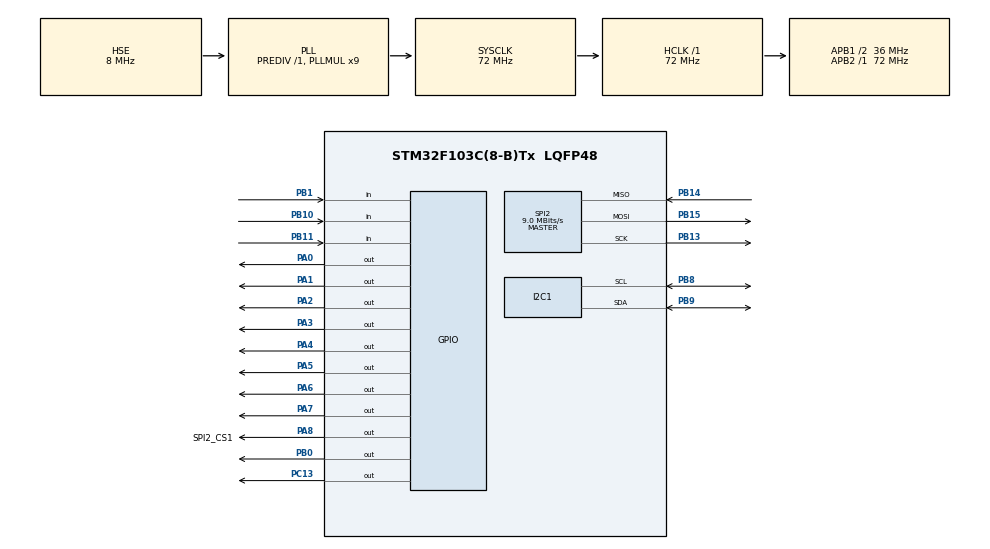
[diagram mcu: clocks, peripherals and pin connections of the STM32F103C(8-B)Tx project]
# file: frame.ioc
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Dma.I2C1_RX.0.Direction=DMA_PERIPH_TO_MEMORY
Dma.I2C1_RX.0.Instance=DMA1_Channel7
Dma.I2C1_RX.0.MemDataAlignment=DMA_MDATAALIGN_BYTE
Dma.I2C1_RX.0.MemInc=DMA_MINC_ENABLE
Dma.I2C1_RX.0.Mode=DMA_NORMAL
Dma.I2C1_RX.0.PeriphDataAlignment=DMA_PDATAALIGN_BYTE
Dma.I2C1_RX.0.PeriphInc=DMA_PINC_DISABLE
Dma.I2C1_RX.0.Priority=DMA_PRIORITY_LOW
Dma.I2C1_TX.1.Direction=DMA_MEMORY_TO_PERIPH
Dma.I2C1_TX.1.Instance=DMA1_Channel6
Dma.I2C1_TX.1.MemDataAlignment=DMA_MDATAALIGN_BYTE
Dma.I2C1_TX.1.MemInc=DMA_MINC_ENABLE
Dma.I2C1_TX.1.Mode=DMA_NORMAL
Dma.I2C1_TX.1.PeriphDataAlignment=DMA_PDATAALIGN_BYTE
Dma.I2C1_TX.1.PeriphInc=DMA_PINC_DISABLE
Dma.I2C1_TX.1.Priority=DMA_PRIORITY_LOW
Dma.Request0=I2C1_RX
Dma.Request1=I2C1_TX
Dma.Request2=SPI2_RX
Dma.Request3=SPI2_TX
Dma.SPI2_RX.2.Direction=DMA_PERIPH_TO_MEMORY
Dma.SPI2_RX.2.Instance=DMA1_Channel4
Dma.SPI2_RX.2.MemDataAlignment=DMA_MDATAALIGN_BYTE
Dma.SPI2_RX.2.MemInc=DMA_MINC_ENABLE
Dma.SPI2_RX.2.Mode=DMA_NORMAL
Dma.SPI2_RX.2.PeriphDataAlignment=DMA_PDATAALIGN_BYTE
Dma.SPI2_RX.2.PeriphInc=DMA_PINC_DISABLE
Dma.SPI2_RX.2.Priority=DMA_PRIORITY_LOW
Dma.SPI2_TX.3.Direction=DMA_MEMORY_TO_PERIPH
Dma.SPI2_TX.3.Instance=DMA1_Channel5
Dma.SPI2_TX.3.MemDataAlignment=DMA_MDATAALIGN_BYTE
Dma.SPI2_TX.3.MemInc=DMA_MINC_ENABLE
Dma.SPI2_TX.3.Mode=DMA_NORMAL
Dma.SPI2_TX.3.PeriphDataAlignment=DMA_PDATAALIGN_BYTE
Dma.SPI2_TX.3.PeriphInc=DMA_PINC_DISABLE
Dma.SPI2_TX.3.Priority=DMA_PRIORITY_LOW
FREERTOS.Mutexes01=IIC_LOCK,Dynamic,NULL
FREERTOS.Mutexes02=SPI_LOCK,Dynamic,NULL
FREERTOS.Queues01=KEY_EVT_Q,8,key_event_msg_t,0,Static,KEY_EVT_QBuffer,KEY_EVT_QControlBlock
FREERTOS.Tasks01=defaultTask,8,128,StartDefaultTask,As weak,NULL,Dynamic,NULL,NULL;KEY_T,48,128,Task_Key_Scan,As weak,NULL,Static,KEY_TBuffer,KEY_TControlBlock;KEY_CMD_T,40,128,Task_Key_Cmd,As weak,NULL,Static,KEY_CMD_TBuffer,KEY_CMD_TControlBlock;OLED_T,16,256,Task_OLED,As weak,NULL,Static,OLED_TBuffer,OLED_TControlBlock
FREERTOS.configMINIMAL_STACK_SIZE=64
I2C1.I2C_Mode=I2C_Fast
Mcu.Family=STM32F1
Mcu.Name=STM32F103C(8-B)Tx
Mcu.Package=LQFP48
NVIC.DMA1_Channel4_IRQn=true\:5\:0\:false\:false\:true\:true\:false\:true\:true
NVIC.DMA1_Channel5_IRQn=true\:5\:0\:false\:false\:true\:true\:false\:true\:true
NVIC.DMA1_Channel6_IRQn=true\:5\:0\:false\:false\:true\:true\:false\:true\:true
NVIC.DMA1_Channel7_IRQn=true\:5\:0\:false\:false\:true\:true\:false\:true\:true
NVIC.I2C1_ER_IRQn=true\:5\:0\:false\:false\:true\:true\:true\:true\:true
NVIC.I2C1_EV_IRQn=true\:5\:0\:false\:false\:true\:true\:true\:true\:true
NVIC.PriorityGroup=NVIC_PRIORITYGROUP_4
NVIC.SPI2_IRQn=true\:5\:0\:false\:false\:true\:true\:true\:true\:true
NVIC.TIM4_IRQn=true\:15\:0\:false\:false\:true\:false\:false\:true\:true
NVIC.TimeBase=TIM4_IRQn
NVIC.TimeBaseIP=TIM4
PA0-WKUP.GPIO_ModeDefaultOutputPP=GPIO_MODE_OUTPUT_PP
PA0-WKUP.GPIO_PuPd=GPIO_PULLDOWN
PA0-WKUP.PinState=GPIO_PIN_RESET
PA0-WKUP.Signal=GPIO_Output
PA1.GPIO_ModeDefaultOutputPP=GPIO_MODE_OUTPUT_PP
PA1.GPIO_PuPd=GPIO_PULLDOWN
PA1.PinState=GPIO_PIN_RESET
PA1.Signal=GPIO_Output
PA13.Mode=Serial_Wire
PA13.Signal=SYS_JTMS-SWDIO
PA14.Mode=Serial_Wire
PA14.Signal=SYS_JTCK-SWCLK
PA2.GPIO_ModeDefaultOutputPP=GPIO_MODE_OUTPUT_PP
PA2.GPIO_PuPd=GPIO_PULLDOWN
PA2.PinState=GPIO_PIN_RESET
PA2.Signal=GPIO_Output
PA3.GPIO_ModeDefaultOutputPP=GPIO_MODE_OUTPUT_PP
PA3.GPIO_PuPd=GPIO_PULLDOWN
PA3.PinState=GPIO_PIN_RESET
PA3.Signal=GPIO_Output
PA4.GPIO_ModeDefaultOutputPP=GPIO_MODE_OUTPUT_PP
PA4.GPIO_PuPd=GPIO_PULLDOWN
PA4.GPIO_Speed=GPIO_SPEED_FREQ_LOW
PA4.PinState=GPIO_PIN_RESET
PA4.Signal=GPIO_Output
PA5.GPIO_ModeDefaultOutputPP=GPIO_MODE_OUTPUT_PP
PA5.GPIO_PuPd=GPIO_PULLDOWN
PA5.PinState=GPIO_PIN_RESET
PA5.Signal=GPIO_Output
PA6.GPIO_ModeDefaultOutputPP=GPIO_MODE_OUTPUT_PP
PA6.GPIO_PuPd=GPIO_PULLDOWN
PA6.PinState=GPIO_PIN_RESET
PA6.Signal=GPIO_Output
PA7.GPIO_ModeDefaultOutputPP=GPIO_MODE_OUTPUT_PP
PA7.GPIO_PuPd=GPIO_PULLDOWN
PA7.PinState=GPIO_PIN_RESET
PA7.Signal=GPIO_Output
PA8.GPIO_Label=SPI2_CS1
PA8.GPIO_PuPd=GPIO_NOPULL
PA8.GPIO_Speed=GPIO_SPEED_FREQ_HIGH
PA8.PinState=GPIO_PIN_SET
PA8.Signal=GPIO_Output
PB0.GPIO_ModeDefaultOutputPP=GPIO_MODE_OUTPUT_PP
PB0.GPIO_PuPd=GPIO_PULLDOWN
PB0.Signal=GPIO_Output
PB1.GPIO_Mode=GPIO_MODE_INPUT
PB1.GPIO_PuPd=GPIO_PULLUP
PB1.Signal=GPIO_Input
PB10.GPIO_Mode=GPIO_MODE_INPUT
PB10.GPIO_PuPd=GPIO_PULLUP
PB10.Signal=GPIO_Input
PB11.GPIO_Mode=GPIO_MODE_INPUT
PB11.GPIO_PuPd=GPIO_PULLUP
PB11.Signal=GPIO_Input
PB13.Mode=Full_Duplex_Master
PB13.Signal=SPI2_SCK
PB14.Mode=Full_Duplex_Master
PB14.Signal=SPI2_MISO
PB15.Mode=Full_Duplex_Master
PB15.Signal=SPI2_MOSI
PB8.Mode=I2C
PB8.Signal=I2C1_SCL
PB9.Mode=I2C
PB9.Signal=I2C1_SDA
PC13-TAMPER-RTC.GPIO_ModeDefaultOutputPP=GPIO_MODE_OUTPUT_PP
PC13-TAMPER-RTC.PinState=GPIO_PIN_SET
PC13-TAMPER-RTC.Signal=GPIO_Output
PD0-OSC_IN.Mode=HSE-External-Oscillator
PD0-OSC_IN.Signal=RCC_OSC_IN
PD1-OSC_OUT.Mode=HSE-External-Oscillator
PD1-OSC_OUT.Signal=RCC_OSC_OUT
ProjectManager.HeapSize=0x200
ProjectManager.StackSize=0x400
ProjectManager.TargetToolchain=CMake
RCC.AHBFreq_Value=72000000
RCC.APB1CLKDivider=RCC_HCLK_DIV2
RCC.APB1Freq_Value=36000000
RCC.APB1TimFreq_Value=72000000
RCC.APB2Freq_Value=72000000
RCC.APB2TimFreq_Value=72000000
RCC.HCLKFreq_Value=72000000
RCC.PLLMUL=RCC_PLL_MUL9
RCC.PLLSourceVirtual=RCC_PLLSOURCE_HSE
RCC.SYSCLKFreq_VALUE=72000000
RCC.SYSCLKSource=RCC_SYSCLKSOURCE_PLLCLK
RCC.USBFreq_Value=72000000
SPI2.BaudRatePrescaler=SPI_BAUDRATEPRESCALER_4
SPI2.CalculateBaudRate=9.0 MBits/s
SPI2.Direction=SPI_DIRECTION_2LINES
SPI2.Mode=SPI_MODE_MASTER
SPI2.VirtualType=VM_MASTER
VP_CRC_VS_CRC.Mode=CRC_Activate
VP_FREERTOS_VS_CMSIS_V2.Mode=CMSIS_V2
VP_SYS_VS_tim4.Mode=TIM4
board=custom

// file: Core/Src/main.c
/* USER CODE BEGIN Header */
/**
  ******************************************************************************
  * @file           : main.c
  * @brief          : Main program body
  ******************************************************************************
  * @attention
  *
  * Copyright (c) 2026 STMicroelectronics.
  * All rights reserved.
  *
  * This software is licensed under terms that can be found in the LICENSE file
  * in the root directory of this software component.
  * If no LICENSE file comes with this software, it is provided AS-IS.
  *
  ******************************************************************************
  */
/* USER CODE END Header */
#include "main.h"
#include "cmsis_os.h"
#include "crc.h"
#include "dma.h"
#include "i2c.h"
#include "spi.h"
#include "gpio.h"

/* USER CODE BEGIN Includes */
#include "svc_key_logic.h"
#include "bsp_iic.h"
/* USER CODE END Includes */

void SystemClock_Config(void);
void MX_FREERTOS_Init(void);

int main(void)
{

  /* MCU Configuration--------------------------------------------------------*/

  /* Reset of all peripherals, Initializes the Flash interface and the Systick. */
  HAL_Init();

  /* Configure the system clock */
  SystemClock_Config();

  /* Initialize all configured peripherals */
  MX_GPIO_Init();
  MX_DMA_Init();
  MX_CRC_Init();
  MX_I2C1_Init();
  MX_SPI2_Init();

  /* Init scheduler */
  osKernelInitialize();  /* Call init function for freertos objects (in cmsis_os2.c) */
  MX_FREERTOS_Init();

  /* Start scheduler */
  osKernelStart();

  /* We should never get here as control is now taken by the scheduler */

  /* Infinite loop */
  while (1)
  {

  }
}

void SystemClock_Config(void)
{
  RCC_OscInitTypeDef RCC_OscInitStruct = {0};
  RCC_ClkInitTypeDef RCC_ClkInitStruct = {0};

  /** Initializes the RCC Oscillators according to the specified parameters
  * in the RCC_OscInitTypeDef structure.
  */
  RCC_OscInitStruct.OscillatorType = RCC_OSCILLATORTYPE_HSE;
  RCC_OscInitStruct.HSEState = RCC_HSE_ON;
  RCC_OscInitStruct.HSEPredivValue = RCC_HSE_PREDIV_DIV1;
  RCC_OscInitStruct.HSIState = RCC_HSI_ON;
  RCC_OscInitStruct.PLL.PLLState = RCC_PLL_ON;
  RCC_OscInitStruct.PLL.PLLSource = RCC_PLLSOURCE_HSE;
  RCC_OscInitStruct.PLL.PLLMUL = RCC_PLL_MUL9;
  if (HAL_RCC_OscConfig(&RCC_OscInitStruct) != HAL_OK)
  {
    Error_Handler();
  }

  /** Initializes the CPU, AHB and APB buses clocks
  */
  RCC_ClkInitStruct.ClockType = RCC_CLOCKTYPE_HCLK|RCC_CLOCKTYPE_SYSCLK
                              |RCC_CLOCKTYPE_PCLK1|RCC_CLOCKTYPE_PCLK2;
  RCC_ClkInitStruct.SYSCLKSource = RCC_SYSCLKSOURCE_PLLCLK;
  RCC_ClkInitStruct.AHBCLKDivider = RCC_SYSCLK_DIV1;
  RCC_ClkInitStruct.APB1CLKDivider = RCC_HCLK_DIV2;
  RCC_ClkInitStruct.APB2CLKDivider = RCC_HCLK_DIV1;

  if (HAL_RCC_ClockConfig(&RCC_ClkInitStruct, FLASH_LATENCY_2) != HAL_OK)
  {
    Error_Handler();
  }
}

void HAL_TIM_PeriodElapsedCallback(TIM_HandleTypeDef *htim)
{
  if (htim->Instance == TIM4)
  {
    HAL_IncTick();
  }
}

void Error_Handler(void)
{
  __disable_irq();
  while (1)
  {
  }
}

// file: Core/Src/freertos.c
/* USER CODE BEGIN Header */
/**
  ******************************************************************************
  * File Name          : freertos.c
  * Description        : Code for freertos applications
  ******************************************************************************
  * @attention
  *
  * Copyright (c) 2026 STMicroelectronics.
  * All rights reserved.
  *
  * This software is licensed under terms that can be found in the LICENSE file
  * in the root directory of this software component.
  * If no LICENSE file comes with this software, it is provided AS-IS.
  *
  ******************************************************************************
  */
/* USER CODE END Header */

#include "FreeRTOS.h"
#include "task.h"
#include "main.h"
#include "cmsis_os.h"

/* USER CODE BEGIN Includes */
#include "svc_key_logic.h"
#include "bsp_iic.h"
#include "bsp_spi.h"
/* USER CODE END Includes */

typedef StaticTask_t osStaticThreadDef_t;
typedef StaticQueue_t osStaticMessageQDef_t;

/* Definitions for defaultTask */
osThreadId_t defaultTaskHandle;
const osThreadAttr_t defaultTask_attributes = {
  .name = "defaultTask",
  .stack_size = 128 * 4,
  .priority = (osPriority_t) osPriorityLow,
};
/* Definitions for KEY_T */
osThreadId_t KEY_THandle;
uint32_t KEY_TBuffer[ 128 ];
osStaticThreadDef_t KEY_TControlBlock;
const osThreadAttr_t KEY_T_attributes = {
  .name = "KEY_T",
  .cb_mem = &KEY_TControlBlock,
  .cb_size = sizeof(KEY_TControlBlock),
  .stack_mem = &KEY_TBuffer[0],
  .stack_size = sizeof(KEY_TBuffer),
  .priority = (osPriority_t) osPriorityRealtime,
};
/* Definitions for KEY_CMD_T */
osThreadId_t KEY_CMD_THandle;
uint32_t KEY_CMD_TBuffer[ 128 ];
osStaticThreadDef_t KEY_CMD_TControlBlock;
const osThreadAttr_t KEY_CMD_T_attributes = {
  .name = "KEY_CMD_T",
  .cb_mem = &KEY_CMD_TControlBlock,
  .cb_size = sizeof(KEY_CMD_TControlBlock),
  .stack_mem = &KEY_CMD_TBuffer[0],
  .stack_size = sizeof(KEY_CMD_TBuffer),
  .priority = (osPriority_t) osPriorityHigh,
};
/* Definitions for OLED_T */
osThreadId_t OLED_THandle;
uint32_t OLED_TBuffer[ 256 ];
osStaticThreadDef_t OLED_TControlBlock;
const osThreadAttr_t OLED_T_attributes = {
  .name = "OLED_T",
  .cb_mem = &OLED_TControlBlock,
  .cb_size = sizeof(OLED_TControlBlock),
  .stack_mem = &OLED_TBuffer[0],
  .stack_size = sizeof(OLED_TBuffer),
  .priority = (osPriority_t) osPriorityBelowNormal,
};
/* Definitions for KEY_EVT_Q */
osMessageQueueId_t KEY_EVT_QHandle;
uint8_t KEY_EVT_QBuffer[ 8 * sizeof( key_event_msg_t ) ];
osStaticMessageQDef_t KEY_EVT_QControlBlock;
const osMessageQueueAttr_t KEY_EVT_Q_attributes = {
  .name = "KEY_EVT_Q",
  .cb_mem = &KEY_EVT_QControlBlock,
  .cb_size = sizeof(KEY_EVT_QControlBlock),
  .mq_mem = &KEY_EVT_QBuffer,
  .mq_size = sizeof(KEY_EVT_QBuffer)
};
/* Definitions for IIC_LOCK */
osMutexId_t IIC_LOCKHandle;
const osMutexAttr_t IIC_LOCK_attributes = {
  .name = "IIC_LOCK"
};
/* Definitions for SPI_LOCK */
osMutexId_t SPI_LOCKHandle;
const osMutexAttr_t SPI_LOCK_attributes = {
  .name = "SPI_LOCK"
};

void StartDefaultTask(void *argument);
void Task_Key_Scan(void *argument);
void Task_Key_Cmd(void *argument);
void Task_OLED(void *argument);

void MX_FREERTOS_Init(void); /* (MISRA C 2004 rule 8.1) */

void MX_FREERTOS_Init(void) {
  /* Create the mutex(es) */
  /* creation of IIC_LOCK */
  IIC_LOCKHandle = osMutexNew(&IIC_LOCK_attributes);

  /* creation of SPI_LOCK */
  SPI_LOCKHandle = osMutexNew(&SPI_LOCK_attributes);

  /* USER CODE BEGIN RTOS_MUTEX */
  /* 初始化 */
  BSP_IIC_Init();
  BSP_SPI_Init();
  Svc_Key_Logic_Init();
  /* USER CODE END RTOS_MUTEX */

  /* Create the queue(s) */
  /* creation of KEY_EVT_Q */
  KEY_EVT_QHandle = osMessageQueueNew (8, sizeof(key_event_msg_t), &KEY_EVT_Q_attributes);

  /* Create the thread(s) */
  /* creation of defaultTask */
  defaultTaskHandle = osThreadNew(StartDefaultTask, NULL, &defaultTask_attributes);

  /* creation of KEY_T */
  KEY_THandle = osThreadNew(Task_Key_Scan, NULL, &KEY_T_attributes);

  /* creation of KEY_CMD_T */
  KEY_CMD_THandle = osThreadNew(Task_Key_Cmd, NULL, &KEY_CMD_T_attributes);

  /* creation of OLED_T */
  OLED_THandle = osThreadNew(Task_OLED, NULL, &OLED_T_attributes);

}

__weak void StartDefaultTask(void *argument)
{
  for(;;)
  {
    osDelay(1);
  }
}

__weak void Task_Key_Scan(void *argument)
{
  for(;;)
  {
    osDelay(1);
  }
}

__weak void Task_Key_Cmd(void *argument)
{
  for(;;)
  {
    osDelay(1);
  }
}

__weak void Task_OLED(void *argument)
{
  for(;;)
  {
    osDelay(1);
  }
}
